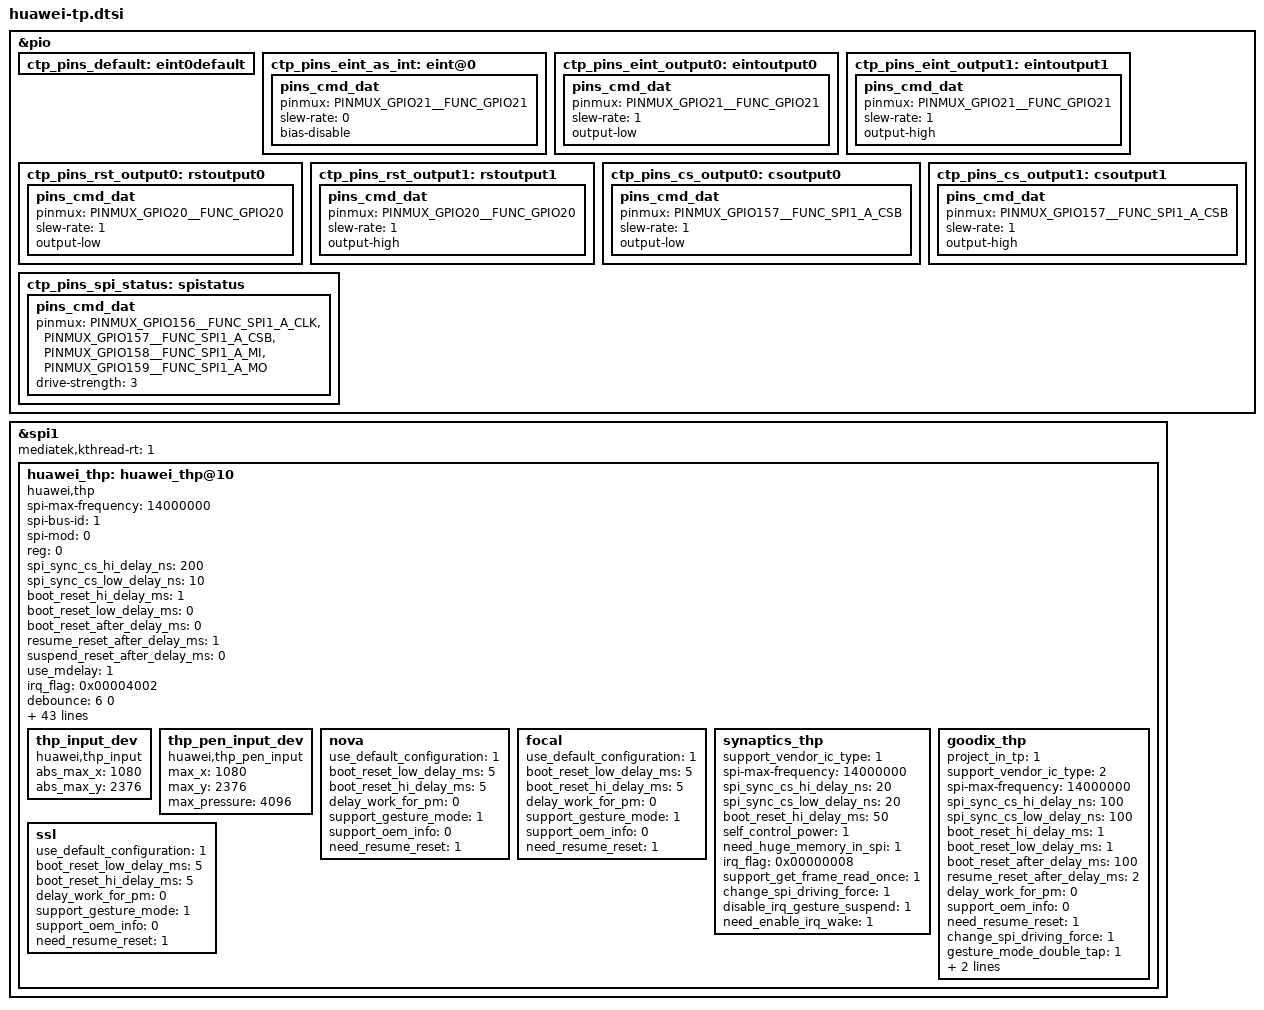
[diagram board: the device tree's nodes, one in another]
&pio {
    ctp_pins_default: eint0default {
    };
    ctp_pins_eint_as_int: eint@0 {
        pins_cmd_dat {
            pinmux = <PINMUX_GPIO21__FUNC_GPIO21>;
            slew-rate = <0>;
            bias-disable;
        };
    };
    ctp_pins_eint_output0: eintoutput0 {
        pins_cmd_dat {
            pinmux = <PINMUX_GPIO21__FUNC_GPIO21>;
            slew-rate = <1>;
            output-low;
        };
    };
    ctp_pins_eint_output1: eintoutput1 {
        pins_cmd_dat {
            pinmux = <PINMUX_GPIO21__FUNC_GPIO21>;
            slew-rate = <1>;
            output-high;
        };
    };
    ctp_pins_rst_output0: rstoutput0 {
        pins_cmd_dat {
            pinmux = <PINMUX_GPIO20__FUNC_GPIO20>;
            slew-rate = <1>;
            output-low;
        };
    };
    ctp_pins_rst_output1: rstoutput1 {
        pins_cmd_dat {
            pinmux = <PINMUX_GPIO20__FUNC_GPIO20>;
            slew-rate = <1>;
            output-high;
        };
    };

    ctp_pins_cs_output0: csoutput0 {
        pins_cmd_dat {
            pinmux = <PINMUX_GPIO157__FUNC_SPI1_A_CSB>;
            slew-rate = <1>;
            output-low;
        };
    };
    ctp_pins_cs_output1: csoutput1 {
        pins_cmd_dat {
            pinmux = <PINMUX_GPIO157__FUNC_SPI1_A_CSB>;
            slew-rate = <1>;
            output-high;
        };
    };
    ctp_pins_spi_status: spistatus   {
        pins_cmd_dat {
            pinmux = <PINMUX_GPIO156__FUNC_SPI1_A_CLK>,
                <PINMUX_GPIO157__FUNC_SPI1_A_CSB>,
                <PINMUX_GPIO158__FUNC_SPI1_A_MI>,
                <PINMUX_GPIO159__FUNC_SPI1_A_MO>;
            drive-strength = <3>;
        };
    };
};

&spi1 {
    status = "ok";
    mediatek,kthread-rt = <1>;
    #address-cells = <1>;
    #size-cells = <0>;
    huawei_thp: huawei_thp@10 {
        compatible = "huawei,thp";
        /* SPI Config */
        spi-max-frequency = <14000000>;
        spi-bus-id = <1>;
        spi-mod = <0>;
        reg = <0>;
        spi_sync_cs_hi_delay_ns  = <200>;
        spi_sync_cs_low_delay_ns = <10>;
        /* Power Config */
        boot_reset_hi_delay_ms = <1>;
        boot_reset_low_delay_ms = <0>;
        boot_reset_after_delay_ms = <0>;
        resume_reset_after_delay_ms = <1>;
        suspend_reset_after_delay_ms = <0>;
        use_mdelay = <1>;
        /* GPIO Config */
        irq_flag = <0x00004002>;
        debounce = <6 0>;
        interrupt-parent = <&pio>;
        interrupts = <21 2 0 0>;
        thp-vcc-type = <1>; /* 0-unsued 1-ldo 2-gpio */
        thp-vcc-supply = <&mt_pmic_vtp_ldo_reg>;
        thp-vcc-value = <3300000>;
        thp-iovdd-type = <1>;
        thp-iovdd-supply = <&mt_pmic_vm18_ldo_reg>;
        thp-iovdd-value = <1800000>;
        /* PinCtrl Config */
        support_pinctrl = <1>;
        pinctrl-names = "default", "idle", "state_eint_as_int", "state_rst_output0",
            "state_rst_output1", "state_cs_output0", "state_cs_output1", "state_spi_status";
        pinctrl-0 = <&ctp_pins_rst_output1 &ctp_pins_cs_output1>;
        pinctrl-1 = <&ctp_pins_rst_output0 &ctp_pins_cs_output0>;
        pinctrl-2 = <&ctp_pins_eint_as_int>;
        pinctrl-3 = <&ctp_pins_rst_output0>;
        pinctrl-4 = <&ctp_pins_rst_output1>;
        pinctrl-5 = <&ctp_pins_cs_output0>;
        pinctrl-6 = <&ctp_pins_cs_output1>;
        pinctrl-7 = <&ctp_pins_spi_status>;
        /* Feature Config */
        proximity_support = <0>;
        hide_product_info_en = <1>;
        support_no_cs_pinctrl_for_mtk = <1>;
        pt_station_test = <0>;
        use_ap_gesture = <1>;
        support_gesture_mode = <1>;
        supported_func_indicater = <0x00>;
        fast_booting_solution = <1>;
        support_fingerprint_switch = <1>;
        pen_supported = <1>;
        pen_mt_enable_flag = <1>;
        project_in_tp = <1>;
        aod_display_support = <1>;
        use_aod_power_ctrl_notify = <1>;
        suspend_delayms_early_to_before = <150>;
        suspend_delayms_before_to_later = <15>;
        resume_delayms_early_to_later = <150>;
        change_spi_driving_force = <1>;
        support_factory_mode_extra_cmd = <1>;
        support_report_interval_adjustment = <1>;
        use_thp_queue = <1>;
        time_interval = <4166>;
        time_min_interval = <3030>;
        platform_type = <1>;
        /* Input Config */
        thp_input_dev {
            compatible = "huawei,thp_input";
            abs_max_x = <1080>;
            abs_max_y = <2376>;
        };
        /* Pen Input Config */
        thp_pen_input_dev {
            compatible = "huawei,thp_pen_input";
            max_x = <1080>;
            max_y = <2376>;
            max_pressure = <4096>;
        };
        nova {
            use_default_configuration = <1>;
            boot_reset_low_delay_ms = <5>;
            boot_reset_hi_delay_ms = <5>;
            delay_work_for_pm = <0>;
            support_gesture_mode = <1>;
            support_oem_info = <0>;
            need_resume_reset = <1>;
        };
        focal {
            use_default_configuration = <1>;
            boot_reset_low_delay_ms = <5>;
            boot_reset_hi_delay_ms = <5>;
            delay_work_for_pm = <0>;
            support_gesture_mode = <1>;
            support_oem_info = <0>;
            need_resume_reset = <1>;
        };
        synaptics_thp {
            support_vendor_ic_type = <1>;
            spi-max-frequency = <14000000>;
            spi_sync_cs_hi_delay_ns = <20>;
            spi_sync_cs_low_delay_ns = <20>;
            boot_reset_hi_delay_ms = <50>;
            self_control_power = <1>;
            need_huge_memory_in_spi = <1>;
            /* IRQF_TRIGGER_LOW 0x00000008 */
            irq_flag = <0x00000008>;
            support_get_frame_read_once = <1>;
            change_spi_driving_force = <1>;
            disable_irq_gesture_suspend = <1>;
            need_enable_irq_wake = <1>;
        };
        goodix_thp {
            project_in_tp = <1>;
            support_vendor_ic_type = <2>;
            spi-max-frequency = <14000000>;
            spi_sync_cs_hi_delay_ns = <100>;
            spi_sync_cs_low_delay_ns = <100>;
            boot_reset_hi_delay_ms = <1>;
            boot_reset_low_delay_ms = <1>;
            boot_reset_after_delay_ms = <100>;
            resume_reset_after_delay_ms = <2>;
            delay_work_for_pm = <0>;
            support_oem_info = <0>;
            need_resume_reset = <1>;
            change_spi_driving_force = <1>;
            gesture_mode_double_tap = <1>;
            disable_irq_gesture_suspend = <1>;
            need_enable_irq_wake = <1>;
        };
        ssl {
            use_default_configuration = <1>;
            boot_reset_low_delay_ms = <5>;
            boot_reset_hi_delay_ms = <5>;
            delay_work_for_pm = <0>;
            support_gesture_mode = <1>;
            support_oem_info = <0>;
            need_resume_reset = <1>;
        };
    };
};
